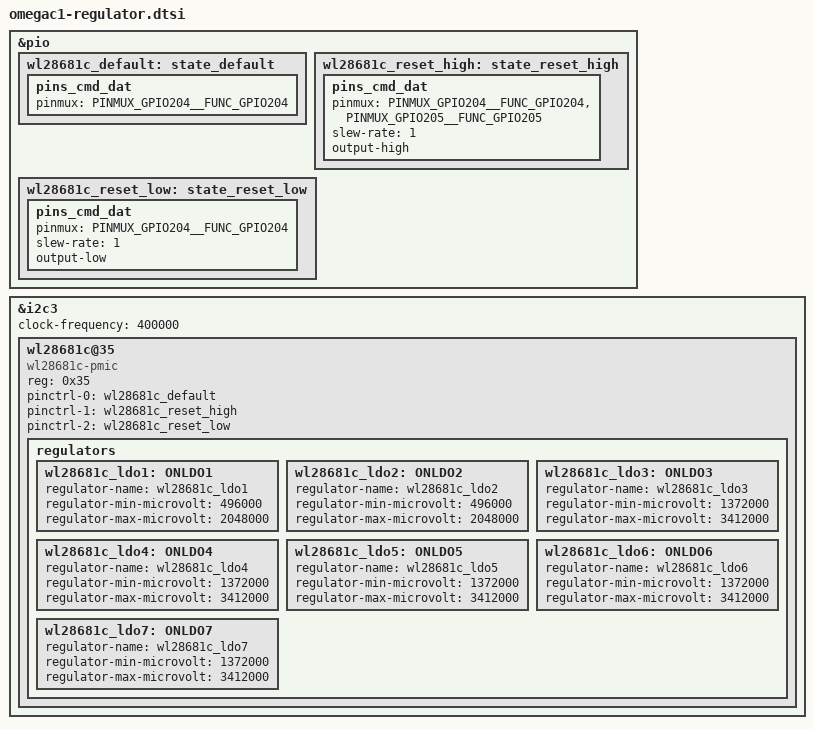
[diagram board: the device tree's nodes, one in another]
// SPDX-License-Identifier: GPL-2.0
/*
 * Copyright (C) 2021 MediaTek Inc.
 */

&pio {
	wl28681c_default: state_default {
		pins_cmd_dat {
			pinmux = <PINMUX_GPIO204__FUNC_GPIO204>;
		};
	};
	// gpio205 pull up to enable LDO1/2 Upstream power supply
	wl28681c_reset_high: state_reset_high {
		pins_cmd_dat {
			pinmux = <PINMUX_GPIO204__FUNC_GPIO204>,
			<PINMUX_GPIO205__FUNC_GPIO205>;
			slew-rate = <1>;
			output-high;
		};
	};
	wl28681c_reset_low: state_reset_low {
		pins_cmd_dat {
			pinmux = <PINMUX_GPIO204__FUNC_GPIO204>;
			//<PINMUX_GPIO205__FUNC_GPIO205>;
			slew-rate = <1>;
			output-low;
		};
	};
};

&i2c3 {
	clock-frequency = <400000>;
	wl28681c@35 {
		compatible = "wl28681c-pmic";
		reg = <0x35>;
		pinctrl-names = "default", "reset_high", "reset_low";
		pinctrl-0 = <&wl28681c_default>;
		pinctrl-1 = <&wl28681c_reset_high>;
		pinctrl-2 = <&wl28681c_reset_low>;
		regulators {
			wl28681c_ldo1:ONLDO1 {
				regulator-name = "wl28681c_ldo1";
				regulator-min-microvolt = <496000>;
				regulator-max-microvolt = <2048000>;
			};
			wl28681c_ldo2:ONLDO2 {
				regulator-name = "wl28681c_ldo2";
				regulator-min-microvolt = <496000>;
				regulator-max-microvolt = <2048000>;
			};
			wl28681c_ldo3:ONLDO3 {
				regulator-name = "wl28681c_ldo3";
				regulator-min-microvolt = <1372000>;
				regulator-max-microvolt = <3412000>;
			};
			wl28681c_ldo4:ONLDO4 {
				regulator-name = "wl28681c_ldo4";
				regulator-min-microvolt = <1372000>;
				regulator-max-microvolt = <3412000>;
			};
			wl28681c_ldo5:ONLDO5 {
				regulator-name = "wl28681c_ldo5";
				regulator-min-microvolt = <1372000>;
				regulator-max-microvolt = <3412000>;
			};
			wl28681c_ldo6:ONLDO6 {
				regulator-name = "wl28681c_ldo6";
				regulator-min-microvolt = <1372000>;
				regulator-max-microvolt = <3412000>;
			};
			wl28681c_ldo7:ONLDO7 {
				regulator-name = "wl28681c_ldo7";
				regulator-min-microvolt = <1372000>;
				regulator-max-microvolt = <3412000>;
			};
		};
	};
};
